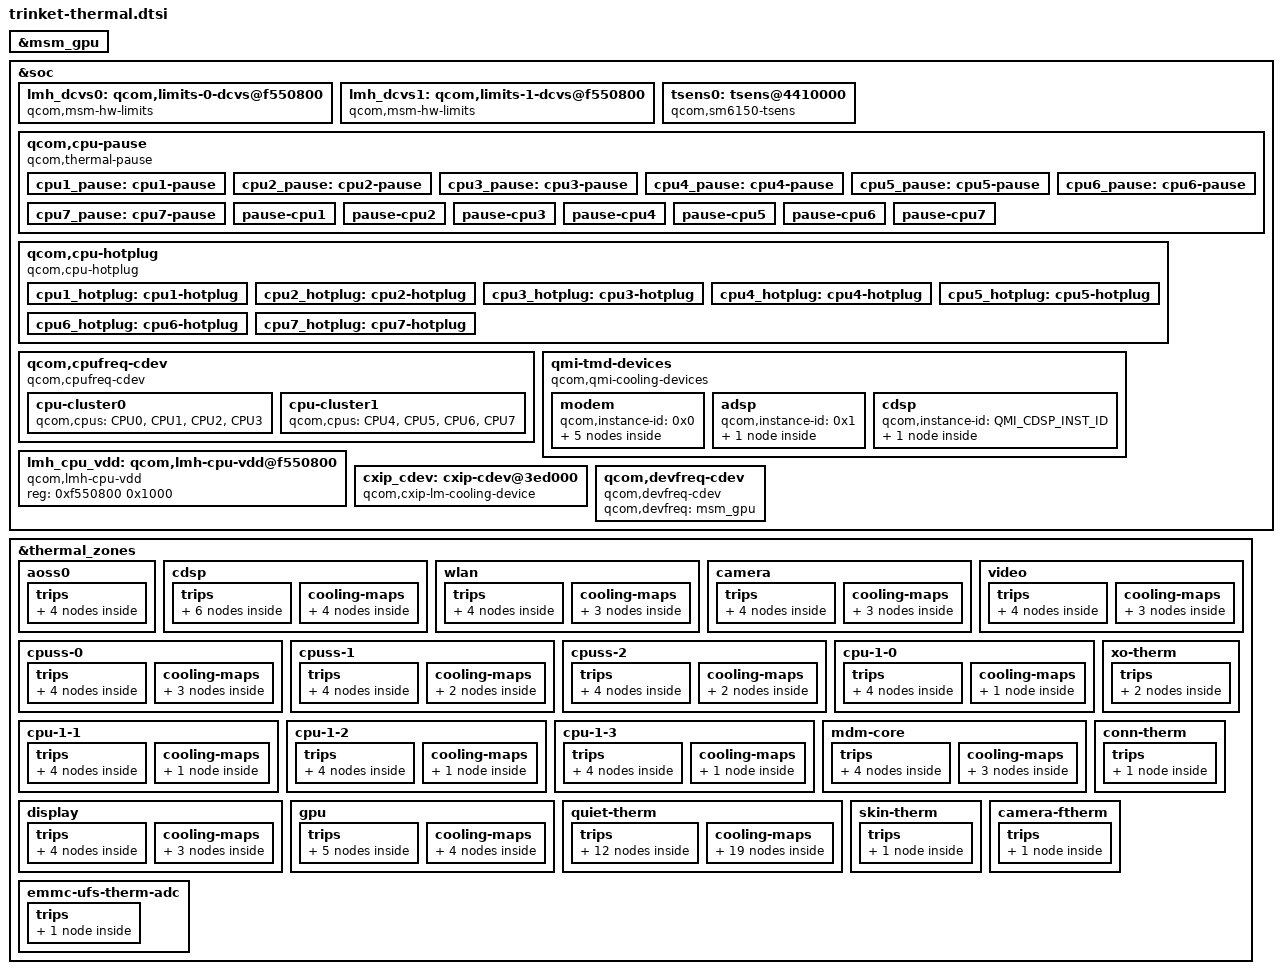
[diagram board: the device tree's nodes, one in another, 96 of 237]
#include <dt-bindings/thermal/thermal_qti.h>

&msm_gpu {
	#cooling-cells = <2>;
};

&soc {
	#address-cells = <1>;
	#size-cells = <1>;
	lmh_dcvs0: qcom,limits-0-dcvs@f550800 {
		compatible = "qcom,msm-hw-limits";
		interrupts = <GIC_SPI 37 IRQ_TYPE_LEVEL_HIGH>;
		qcom,affinity = <0>;
		reg = <0xf550800 0x1000>,
			<0xf521000 0x1000>;
	};

	lmh_dcvs1: qcom,limits-1-dcvs@f550800 {
		compatible = "qcom,msm-hw-limits";
		interrupts = <GIC_SPI 37 IRQ_TYPE_LEVEL_HIGH>;
		qcom,affinity = <1>;
		reg = <0xf550800 0x1000>,
			<0xf523000 0x1000>;
	};

	tsens0: tsens@4410000 {
		compatible = "qcom,sm6150-tsens";
		reg = <0x4410000 0x8>,
		      <0x4411000 0x1ff>;
		reg-names = "tsens_srot_physical",
			    "tsens_tm_physical";
		interrupts-extended = <&intc GIC_SPI 190 IRQ_TYPE_LEVEL_HIGH>,
			<&mpm 2 IRQ_TYPE_LEVEL_HIGH>;
		interrupt-names = "tsens-critical",
			"tsens-upper-lower";
		#thermal-sensor-cells = <1>;
	};

	qcom,cpu-pause {
		compatible = "qcom,thermal-pause";

		cpu1_pause: cpu1-pause {
			qcom,cpus = <&CPU1>;
			qcom,cdev-alias = "thermal-pause-2";
			#cooling-cells = <2>;
		};

		cpu2_pause: cpu2-pause {
			qcom,cpus = <&CPU2>;
			qcom,cdev-alias = "thermal-pause-4";
			#cooling-cells = <2>;
		};

		cpu3_pause: cpu3-pause {
			qcom,cpus = <&CPU3>;
			qcom,cdev-alias = "thermal-pause-8";
			#cooling-cells = <2>;
		};

		cpu4_pause: cpu4-pause {
			qcom,cpus = <&CPU4>;
			qcom,cdev-alias = "thermal-pause-10";
			#cooling-cells = <2>;
		};

		cpu5_pause: cpu5-pause {
			qcom,cpus = <&CPU5>;
			qcom,cdev-alias = "thermal-pause-20";
			#cooling-cells = <2>;
		};

		cpu6_pause: cpu6-pause {
			qcom,cpus = <&CPU6>;
			qcom,cdev-alias = "thermal-pause-40";
			#cooling-cells = <2>;
		};

		cpu7_pause: cpu7-pause {
			qcom,cpus = <&CPU7>;
			qcom,cdev-alias = "thermal-pause-80";
			#cooling-cells = <2>;
		};

		/* Thermal-engine cooling devices */
		pause-cpu1 {
			qcom,cpus = <&CPU1>;
			qcom,cdev-alias = "pause-cpu1";
		};

		pause-cpu2 {
			qcom,cpus = <&CPU2>;
			qcom,cdev-alias = "pause-cpu2";
		};

		pause-cpu3 {
			qcom,cpus = <&CPU3>;
			qcom,cdev-alias = "pause-cpu3";
		};

		pause-cpu4 {
			qcom,cpus = <&CPU4>;
			qcom,cdev-alias = "pause-cpu4";
		};

		pause-cpu5 {
			qcom,cpus = <&CPU5>;
			qcom,cdev-alias = "pause-cpu5";
		};

		pause-cpu6 {
			qcom,cpus = <&CPU6>;
			qcom,cdev-alias = "pause-cpu6";
		};

		pause-cpu7 {
			qcom,cpus = <&CPU7>;
			qcom,cdev-alias = "pause-cpu7";
		};
	};

	qcom,cpu-hotplug {
		compatible = "qcom,cpu-hotplug";

		cpu1_hotplug: cpu1-hotplug {
			qcom,cpu = <&CPU1>;
			qcom,cdev-alias = "cpu-hotplug1";
			#cooling-cells = <2>;
		};

		cpu2_hotplug: cpu2-hotplug {
			qcom,cpu = <&CPU2>;
			qcom,cdev-alias = "cpu-hotplug2";
			#cooling-cells = <2>;
		};

		cpu3_hotplug: cpu3-hotplug {
			qcom,cpu = <&CPU3>;
			qcom,cdev-alias = "cpu-hotplug3";
			#cooling-cells = <2>;
		};

		cpu4_hotplug: cpu4-hotplug {
			qcom,cpu = <&CPU4>;
			qcom,cdev-alias = "cpu-hotplug4";
			#cooling-cells = <2>;
		};

		cpu5_hotplug: cpu5-hotplug {
			qcom,cpu = <&CPU5>;
			qcom,cdev-alias = "cpu-hotplug5";
			#cooling-cells = <2>;
		};

		cpu6_hotplug: cpu6-hotplug {
			qcom,cpu = <&CPU6>;
			qcom,cdev-alias = "cpu-hotplug6";
			#cooling-cells = <2>;
		};

		cpu7_hotplug: cpu7-hotplug {
			qcom,cpu = <&CPU7>;
			qcom,cdev-alias = "cpu-hotplug7";
			#cooling-cells = <2>;
		};
	};

	qcom,cpufreq-cdev {
		compatible = "qcom,cpufreq-cdev";
		cpu-cluster0 {
			qcom,cpus = <&CPU0 &CPU1 &CPU2 &CPU3>;
		};

		cpu-cluster1 {
			qcom,cpus = <&CPU4 &CPU5 &CPU6 &CPU7>;
		};
	};

	qmi-tmd-devices {
		compatible = "qcom,qmi-cooling-devices";

		modem {
			qcom,instance-id = <0x0>;

			modem_pa: modem_pa {
				qcom,qmi-dev-name = "pa";
				#cooling-cells = <2>;
			};

			modem_proc: modem_proc {
				qcom,qmi-dev-name = "modem";
				#cooling-cells = <2>;
			};

			modem_current: modem_current {
				qcom,qmi-dev-name = "modem_current";
				#cooling-cells = <2>;
			};

			modem_skin: modem_skin {
				qcom,qmi-dev-name = "modem_skin";
				#cooling-cells = <2>;
			};

			modem_vdd: modem_vdd {
				qcom,qmi-dev-name = "cpuv_restriction_cold";
				#cooling-cells = <2>;
			};
		};

		adsp {
			qcom,instance-id = <0x1>;

			adsp_vdd: adsp_vdd {
				qcom,qmi-dev-name = "cpuv_restriction_cold";
				#cooling-cells = <2>;
			};
		};

		cdsp {
			qcom,instance-id = <QMI_CDSP_INST_ID>;

			cdsp_vdd: cdsp_vdd {
				qcom,qmi-dev-name = "cpuv_restriction_cold";
				#cooling-cells = <2>;
			};
		};
	};

	lmh_cpu_vdd: qcom,lmh-cpu-vdd@f550800 {
		compatible = "qcom,lmh-cpu-vdd";
		reg =  <0xf550800 0x1000>;
	};

	cxip_cdev: cxip-cdev@3ed000 {
		compatible = "qcom,cxip-lm-cooling-device";
		reg = <0x3ed000 0xc00c>;
		qcom,thermal-client-offset = <0x9000>;
		/* 2nd and 3rd offsets to bypass VICTIM1 */
		qcom,bypass-client-list = <0xa004 0xc004 0xc008>;
		#cooling-cells = <2>;
	};

	qcom,devfreq-cdev {
		compatible = "qcom,devfreq-cdev";
		qcom,devfreq = <&msm_gpu>;
	};
};

&thermal_zones {
	aoss0 {
		polling-delay-passive = <0>;
		polling-delay = <0>;
		thermal-sensors = <&tsens0 0>;
		trips {
			thermal-engine-config {
				temperature = <125000>;
				hysteresis = <1000>;
				type = "passive";
			};

			thermal-hal-config {
				temperature = <125000>;
				hysteresis = <1000>;
				type = "passive";
			};

			reset-mon-1-cfg {
				temperature = <110000>;
				hysteresis = <5000>;
				type = "passive";
			};

			reset-mon-2-cfg {
				temperature = <115000>;
				hysteresis = <5000>;
				type = "passive";
			};
		};
	};

	cdsp {
		polling-delay-passive = <10>;
		polling-delay = <0>;
		thermal-sensors = <&tsens0 1>;
		trips {
			thermal-engine-config {
				temperature = <125000>;
				hysteresis = <1000>;
				type = "passive";
			};

			reset-mon-1-cfg {
				temperature = <110000>;
				hysteresis = <5000>;
				type = "passive";
			};

			reset-mon-2-cfg {
				temperature = <115000>;
				hysteresis = <5000>;
				type = "passive";
			};

			cdsp_trip0: cdsp-trip0 {
				temperature = <95000>;
				hysteresis = <20000>;
				type = "passive";
			};

			cdsp_trip1: cdsp-trip1 {
				temperature = <95000>;
				hysteresis = <0>;
				type = "passive";
			};

			cdsp_cx_mon: cdsp-cx-mon {
				temperature = <100000>;
				hysteresis = <5000>;
				type = "passive";
			};
		};

		cooling-maps {
			cxip-cdev {
				trip = <&cdsp_trip0>;
				cooling-device = <&cxip_cdev 1 1>;
			};

			cdsp-cx-cdev0 {
				trip = <&cdsp_cx_mon>;
				cooling-device = <&msm_gpu 6 6>;
			};

			cdsp-cx-cdev1 {
				trip = <&cdsp_cx_mon>;
				cooling-device = <&modem_proc 3 3>;
			};

			cdsp-cx-cdev2 {
				trip = <&cdsp_cx_mon>;
				cooling-device = <&modem_pa 3 3>;
			};
		};
	};

	wlan {
		polling-delay-passive = <0>;
		polling-delay = <0>;
		thermal-sensors = <&tsens0 2>;
		trips {
			thermal-engine-config {
				temperature = <125000>;
				hysteresis = <1000>;
				type = "passive";
			};

			reset-mon-1-cfg {
				temperature = <110000>;
				hysteresis = <5000>;
				type = "passive";
			};

			reset-mon-2-cfg {
				temperature = <115000>;
				hysteresis = <5000>;
				type = "passive";
			};

			wlan_cx_mon: wlan-cx-mon {
				temperature = <100000>;
				hysteresis = <5000>;
				type = "passive";
			};
		};

		cooling-maps {
			wlan-cx-cdev0 {
				trip = <&wlan_cx_mon>;
				cooling-device = <&msm_gpu 6 6>;
			};

			wlan-cx-cdev1 {
				trip = <&wlan_cx_mon>;
				cooling-device = <&modem_proc 3 3>;
			};

			wlan-cx-cdev2 {
				trip = <&wlan_cx_mon>;
				cooling-device = <&modem_pa 3 3>;
			};
		};
	};

	camera {
		polling-delay-passive = <0>;
		polling-delay = <0>;
		thermal-sensors = <&tsens0 3>;
		trips {
			thermal-engine-config {
				temperature = <125000>;
				hysteresis = <1000>;
				type = "passive";
			};

			reset-mon-1-cfg {
				temperature = <110000>;
				hysteresis = <5000>;
				type = "passive";
			};

			reset-mon-2-cfg {
				temperature = <115000>;
				hysteresis = <5000>;
				type = "passive";
			};

			camera_cx_mon: camera-cx-mon {
				temperature = <100000>;
				hysteresis = <5000>;
				type = "passive";
			};
		};

		cooling-maps {
			camera-cx-cdev0 {
				trip = <&camera_cx_mon>;
				cooling-device = <&msm_gpu 6 6>;
			};

			camera-cx-cdev1 {
				trip = <&camera_cx_mon>;
				cooling-device = <&modem_proc 3 3>;
			};

			camera-cx-cdev2 {
				trip = <&camera_cx_mon>;
				cooling-device = <&modem_pa 3 3>;
			};
		};
	};

	video {
		polling-delay-passive = <0>;
		polling-delay = <0>;
		thermal-sensors = <&tsens0 4>;
		trips {
			thermal-engine-config {
				temperature = <125000>;
				hysteresis = <1000>;
				type = "passive";
			};

			reset-mon-1-cfg {
				temperature = <110000>;
				hysteresis = <5000>;
				type = "passive";
			};

			reset-mon-2-cfg {
				temperature = <115000>;
				hysteresis = <5000>;
				type = "passive";
			};

			video_cx_mon: video-cx-mon {
				temperature = <100000>;
				hysteresis = <5000>;
				type = "passive";
			};
		};

		cooling-maps {
			video-cx-cdev0 {
				trip = <&video_cx_mon>;
				cooling-device = <&msm_gpu 6 6>;
			};

			video-cx-cdev1 {
				trip = <&video_cx_mon>;
				cooling-device = <&modem_proc 3 3>;
			};

			video-cx-cdev2 {
				trip = <&video_cx_mon>;
				cooling-device = <&modem_pa 3 3>;
			};
		};
	};

	cpuss-0 {
		polling-delay-passive = <0>;
		polling-delay = <0>;
		thermal-sensors = <&tsens0 6>;
		trips {
			thermal-engine-config {
				temperature = <125000>;
				hysteresis = <1000>;
				type = "passive";
			};

			reset-mon-1-cfg {
				temperature = <110000>;
				hysteresis = <5000>;
				type = "passive";
			};

			reset-mon-2-cfg {
				temperature = <115000>;
				hysteresis = <5000>;
				type = "passive";
			};

			silv_cpus_config: silv-cpus-config {
				temperature = <110000>;
				hysteresis = <10000>;
				type = "passive";
			};
		};

		cooling-maps {
			cpu1_cdev {
				trip = <&silv_cpus_config>;
				cooling-device = <&cpu1_pause 1 1>;
			};

			cpu2_cdev {
				trip = <&silv_cpus_config>;
				cooling-device = <&cpu2_pause 1 1>;
			};

			cpu3_cdev {
				trip = <&silv_cpus_config>;
				cooling-device = <&cpu3_pause 1 1>;
			};
		};
	};

	cpuss-1 {
		polling-delay-passive = <0>;
		polling-delay = <0>;
		thermal-sensors = <&tsens0 7>;
		trips {
			thermal-engine-config {
				temperature = <125000>;
				hysteresis = <1000>;
				type = "passive";
			};

			reset-mon-1-cfg {
				temperature = <110000>;
				hysteresis = <5000>;
				type = "passive";
			};

			reset-mon-2-cfg {
				temperature = <115000>;
				hysteresis = <5000>;
				type = "passive";
			};

			cpu5_7_config: cpu5-7-config {
				temperature = <110000>;
				hysteresis = <10000>;
				type = "passive";
			};
		};

		cooling-maps {
			cpu5_cdev {
				trip = <&cpu5_7_config>;
				cooling-device = <&cpu5_pause 1 1>;
			};

			cpu7_cdev {
				trip = <&cpu5_7_config>;
				cooling-device = <&cpu7_pause 1 1>;
			};
		};
	};

	cpuss-2 {
		polling-delay-passive = <0>;
		polling-delay = <0>;
		thermal-sensors = <&tsens0 8>;
		trips {
			thermal-engine-config {
				temperature = <125000>;
				hysteresis = <1000>;
				type = "passive";
			};

			reset-mon-1-cfg {
				temperature = <110000>;
				hysteresis = <5000>;
				type = "passive";
			};

			reset-mon-2-cfg {
				temperature = <115000>;
				hysteresis = <5000>;
				type = "passive";
			};

			cpu4_6_config: cpu-4-6-config {
				temperature = <110000>;
				hysteresis = <10000>;
				type = "passive";
			};
		};

		cooling-maps {
			cpu4_cdev {
				trip = <&cpu4_6_config>;
				cooling-device = <&cpu4_pause 1 1>;
			};

			cpu6_cdev {
				trip = <&cpu4_6_config>;
				cooling-device = <&cpu6_pause 1 1>;
			};
		};
	};

	cpu-1-0 {
		polling-delay-passive = <0>;
		polling-delay = <0>;
		thermal-sensors = <&tsens0 9>;
		trips {
			thermal-engine-config {
				temperature = <125000>;
				hysteresis = <1000>;
				type = "passive";
			};

			reset-mon-1-cfg {
				temperature = <110000>;
				hysteresis = <5000>;
				type = "passive";
			};

			reset-mon-2-cfg {
				temperature = <115000>;
				hysteresis = <5000>;
				type = "passive";
			};

			cpu4_config: cpu4-config {
				temperature = <110000>;
				hysteresis = <10000>;
				type = "passive";
			};
		};

		cooling-maps {
			cpu4_cdev {
				trip = <&cpu4_config>;
				cooling-device = <&cpu4_pause 1 1>;
			};
		};
	};

	cpu-1-1 {
		polling-delay-passive = <0>;
		polling-delay = <0>;
		thermal-sensors = <&tsens0 10>;
		trips {
			thermal-engine-config {
				temperature = <125000>;
				hysteresis = <1000>;
				type = "passive";
			};

			reset-mon-1-cfg {
				temperature = <110000>;
				hysteresis = <5000>;
				type = "passive";
			};

			reset-mon-2-cfg {
				temperature = <115000>;
				hysteresis = <5000>;
				type = "passive";
			};

			cpu5_config: cpu5-config {
				temperature = <110000>;
				hysteresis = <10000>;
				type = "passive";
			};
		};

		cooling-maps {
			cpu5_cdev {
				trip = <&cpu5_config>;
				cooling-device = <&cpu5_pause 1 1>;
			};
		};
	};

	cpu-1-2 {
		polling-delay-passive = <0>;
		polling-delay = <0>;
		thermal-sensors = <&tsens0 11>;
		trips {
			thermal-engine-config {
				temperature = <125000>;
				hysteresis = <1000>;
				type = "passive";
			};

			reset-mon-1-cfg {
				temperature = <110000>;
				hysteresis = <5000>;
				type = "passive";
			};

			reset-mon-2-cfg {
				temperature = <115000>;
				hysteresis = <5000>;
				type = "passive";
			};

			cpu6_config: cpu6-config {
				temperature = <110000>;
				hysteresis = <10000>;
				type = "passive";
			};
		};

		cooling-maps {
			cpu6_cdev {
				trip = <&cpu6_config>;
				cooling-device = <&cpu6_pause 1 1>;
			};
		};
	};

	cpu-1-3 {
		polling-delay-passive = <0>;
		polling-delay = <0>;
		thermal-sensors = <&tsens0 12>;
		trips {
			thermal-engine-config {
				temperature = <125000>;
				hysteresis = <1000>;
				type = "passive";
			};

			reset-mon-1-cfg {
				temperature = <110000>;
				hysteresis = <5000>;
				type = "passive";
			};

			reset-mon-2-cfg {
				temperature = <115000>;
				hysteresis = <5000>;
				type = "passive";
			};

			cpu7_config: cpu7-config {
				temperature = <110000>;
				hysteresis = <10000>;
				type = "passive";
			};
		};

		cooling-maps {
			cpu7_cdev {
				trip = <&cpu7_config>;
				cooling-device = <&cpu7_pause 1 1>;
			};
		};
	};

	mdm-core {
		polling-delay-passive = <0>;
		polling-delay = <0>;
		thermal-sensors = <&tsens0 13>;
		trips {
			thermal-engine-config {
				temperature = <125000>;
				hysteresis = <1000>;
				type = "passive";
			};

			reset-mon-1-cfg {
				temperature = <110000>;
				hysteresis = <5000>;
				type = "passive";
			};

			reset-mon-2-cfg {
				temperature = <115000>;
				hysteresis = <5000>;
				type = "passive";
			};

			mdm_core_cx_mon: mdm-core-cx-mon {
				temperature = <100000>;
				hysteresis = <5000>;
				type = "passive";
			};
		};

		cooling-maps {
			mdm-cx-cdev0 {
				trip = <&mdm_core_cx_mon>;
				cooling-device = <&msm_gpu 6 6>;
			};

			mdm-cx-cdev1 {
				trip = <&mdm_core_cx_mon>;
				cooling-device = <&modem_proc 3 3>;
			};

			mdm-cx-cdev2 {
				trip = <&mdm_core_cx_mon>;
				cooling-device = <&modem_pa 3 3>;
			};
		};
	};

	display {
		polling-delay-passive = <0>;
		polling-delay = <0>;
		thermal-sensors = <&tsens0 14>;
		trips {
			thermal-engine-config {
				temperature = <125000>;
				hysteresis = <1000>;
				type = "passive";
			};

			reset-mon-1-cfg {
				temperature = <110000>;
				hysteresis = <5000>;
				type = "passive";
			};

			reset-mon-2-cfg {
				temperature = <115000>;
				hysteresis = <5000>;
				type = "passive";
			};

			display_cx_mon: display-cx-mon {
				temperature = <100000>;
				hysteresis = <5000>;
				type = "passive";
			};
		};

		cooling-maps {
			display-cx-cdev0 {
				trip = <&display_cx_mon>;
				cooling-device = <&msm_gpu 6 6>;
			};

			display-cx-cdev1 {
				trip = <&display_cx_mon>;
				cooling-device = <&modem_proc 3 3>;
			};

			display-cx-cdev2 {
				trip = <&display_cx_mon>;
				cooling-device = <&modem_pa 3 3>;
			};
		};
	};

	gpu {
		polling-delay-passive = <10>;
		polling-delay = <0>;
		thermal-sensors = <&tsens0 15>;
		trips {
			thermal-engine-config {
				temperature = <125000>;
				hysteresis = <1000>;
				type = "passive";
			};

			reset-mon-1-cfg {
				temperature = <110000>;
				hysteresis = <5000>;
				type = "passive";
			};

			reset-mon-2-cfg {
				temperature = <115000>;
				hysteresis = <5000>;
				type = "passive";
			};

			gpu_step_trip: gpu-trip {
				temperature = <95000>;
				hysteresis = <0>;
				type = "passive";
			};

			gpu_cx_mon: gpu-cx-mon {
				temperature = <100000>;
				hysteresis = <5000>;
				type = "passive";
			};
		};

		cooling-maps {
			gpu_cdev {
				trip = <&gpu_step_trip>;
				cooling-device = <&msm_gpu THERMAL_NO_LIMIT
							THERMAL_NO_LIMIT>;
			};

			gpu-cx-cdev0 {
				trip = <&gpu_cx_mon>;
				cooling-device = <&msm_gpu 6 6>;
			};

			gpu-cx-cdev1 {
				trip = <&gpu_cx_mon>;
				cooling-device = <&modem_proc 3 3>;
			};

			gpu-cx-cdev2 {
				trip = <&gpu_cx_mon>;
				cooling-device = <&modem_pa 3 3>;
			};
		};
	};

	quiet-therm {
		polling-delay-passive = <2000>;
		polling-delay = <5000>;
		thermal-sensors = <&pm6125_adc_tm 1>;
		trips {
			thermal-engine-config {
				temperature = <125000>;
				hysteresis = <1000>;
				type = "passive";
			};

			batt_trip0: batt-trip0 {
				temperature = <45000>;
				hysteresis = <2000>;
				type = "passive";
			};

			gold_trip: gold-trip {
				temperature = <46000>;
				hysteresis = <0>;
				type = "passive";
			};

			modem_trip0: modem-trip0 {
				temperature = <46000>;
				hysteresis = <4000>;
				type = "passive";
			};

			batt_trip1: batt-trip1 {
				temperature = <47000>;
				hysteresis = <2000>;
				type = "passive";
			};

			modem_trip1: modem-trip1 {
				temperature = <48000>;
				hysteresis = <2000>;
				type = "passive";
			};

			skin_gpu_trip: skin-gpu-trip {
				temperature = <48000>;
				hysteresis = <0>;
				type = "passive";
			};

			batt_trip2: batt-trip2 {
				temperature = <49000>;
				hysteresis = <2000>;
				type = "passive";
			};

			modem_trip2: modem-trip2 {
				temperature = <50000>;
				hysteresis = <2000>;
				type = "passive";
			};

			batt_trip3: batt-trip3 {
				temperature = <51000>;
				hysteresis = <2000>;
				type = "passive";
			};

			silver_trip: silver-trip {
				temperature = <52000>;
				hysteresis = <0>;
				type = "passive";
			};

			cx_emer_trip: cx-emer-trip {
				temperature = <52000>;
				hysteresis = <4000>;
				type = "passive";
			};
		};

		cooling-maps {
			skin_cpu4 {
				trip = <&gold_trip>;
				cooling-device =
					/* throttle from fmax to 1401600KHz */
					<&CPU4 0 3>;
			};

			skin_cpu5 {
				trip = <&gold_trip>;
				cooling-device = <&CPU5 0 3>;
			};

			skin_cpu6 {
				trip = <&gold_trip>;
				cooling-device = <&CPU6 0 3>;
			};

			skin_cpu7 {
				trip = <&gold_trip>;
				cooling-device = <&CPU7 0 3>;
			};

			skin_cpu0 {
				trip = <&silver_trip>;
				/* throttle from fmax to 1420800KHz */
				cooling-device = <&CPU0 0 2>;
			};

			skin_cpu1 {
				trip = <&silver_trip>;
				cooling-device = <&CPU1 0 2>;
			};

			skin_cpu2 {
				trip = <&silver_trip>;
				cooling-device = <&CPU2 0 2>;
			};

			skin_cpu3 {
				trip = <&silver_trip>;
				cooling-device = <&CPU3 0 2>;
			};

			skin_gpu {
				trip = <&skin_gpu_trip>;
				cooling-device = <&msm_gpu 0 4>;
			};

			modem_lvl1 {
				trip = <&modem_trip1>;
				cooling-device = <&modem_pa 1 1>;
			};

			modem_lvl2 {
				trip = <&modem_trip2>;
				cooling-device = <&modem_pa 2 2>;
			};

			modem_lvl3 {
				trip = <&cx_emer_trip>;
				cooling-device = <&modem_pa 3 3>;
			};

			modem_proc_lvl1 {
				trip = <&modem_trip0>;
				cooling-device = <&modem_proc 1 1>;
			};

			modem_proc_lvl3 {
				trip = <&cx_emer_trip>;
				cooling-device = <&modem_proc 3 3>;
			};

			battery_lvl0 {
				trip = <&batt_trip0>;
				cooling-device = <&pmi632_charger 1 1>;
			};

			battery_lvl1 {
				trip = <&batt_trip1>;
				cooling-device = <&pmi632_charger 2 2>;
			};

			battery_lvl2 {
				trip = <&batt_trip2>;
				cooling-device = <&pmi632_charger 4 4>;
			};

			battery_lvl3 {
				trip = <&batt_trip3>;
				cooling-device = <&pmi632_charger 5 5>;
			};

			cx_skin_gpu {
				trip = <&cx_emer_trip>;
				cooling-device = <&msm_gpu 6 6>;
			};
		};
	};

	xo-therm {
		polling-delay-passive = <0>;
		polling-delay = <0>;
		thermal-sensors = <&pm6125_adc_tm 2>;
		trips {
			active-config0 {
				temperature = <125000>;
				hysteresis = <1000>;
				type = "passive";
			};

			active-config1 {
				temperature = <125000>;
				hysteresis = <1000>;
				type = "passive";
			};
		};
	};

	conn-therm {
		polling-delay-passive = <0>;
		polling-delay = <0>;
		thermal-sensors = <&pmi632_adc_tm 0>;
		trips {
			active-config0 {
				temperature = <125000>;
				hysteresis = <1000>;
				type = "passive";
			};
		};
	};

	skin-therm {
		polling-delay-passive = <0>;
		polling-delay = <0>;
		thermal-sensors = <&pmi632_adc_tm 2>;
		trips {
			active-config0 {
				temperature = <125000>;
				hysteresis = <1000>;
				type = "passive";
			};
		};
	};

	camera-ftherm {
		polling-delay-passive = <0>;
		polling-delay = <5000>;
		thermal-sensors = <&pm6125_adc_tm_iio 0>;
		trips {
			active-config0 {
				temperature = <125000>;
				hysteresis = <1000>;
				type = "passive";
			};
		};
	};

	emmc-ufs-therm-adc {
		polling-delay-passive = <0>;
		polling-delay = <5000>;
		thermal-sensors = <&pm6125_adc_tm_iio 1>;
		trips {
			active-config0 {
				temperature = <125000>;
				hysteresis = <1000>;
				type = "passive";
			};
		};
	};
};

